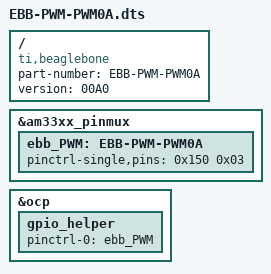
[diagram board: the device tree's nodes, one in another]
/*
 * Copyright (C) 2013 CircuitCo
 *
 * Virtual cape for UART1 on connector pins P9.24 P9.26
 *
 * This program is free software; you can redistribute it and/or modify
 * it under the terms of the GNU General Public License version 2 as
 * published by the Free Software Foundation.
 */
/dts-v1/;
/plugin/;

/ {
    compatible = "ti,beaglebone", "ti,beaglebone-black";

        /* identification */
        part-number = "EBB-PWM-PWM0A";
        version = "00A0";


        fragment@0 {
                target = <&am33xx_pinmux>;
                __overlay__ {
                        ebb_PWM: EBB-PWM-PWM0A {
                                pinctrl-single,pins = <
                                        0x150 0x03 /* P9.22 turn it as GPIO, PULLDOWN | MODE 3 */
                                        
                                >;
                        };
                };
        };

    fragment@1 {
                target = <&ocp>;    /* really ehrpwm0a */
                __overlay__ {
                    gpio_helper{
                        compatible-"gpio-of-helper"
                        status = "okay";
                        pinctrl-names = "default";
                        pinctrl-0 = <&ebb_PWM>;
                    };
                };
        };
};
